# ATSAM4LC2C register map
Vendor: Atmel Corporation; Series: SAM4L; File version: B
CPU: CM4 r0p1, little endian, MPU, no FPU, 4 interrupt priority bits
Registers are 32-bit, write-only, reset 0x0 unless marked. A register's access mark holds for its fields unless they carry their own. Offsets are from the block's base; [hi:lo] are bit positions; {n}, {i} and the like mark numbered series; 'fields as' and 'values as' point back to an identical list.

## FREQM — Frequency Meter
Base 0x400E0C00; register names take the prefix FREQM_
0x00 CTRL — Control register
  [0] START — Start frequency measurement
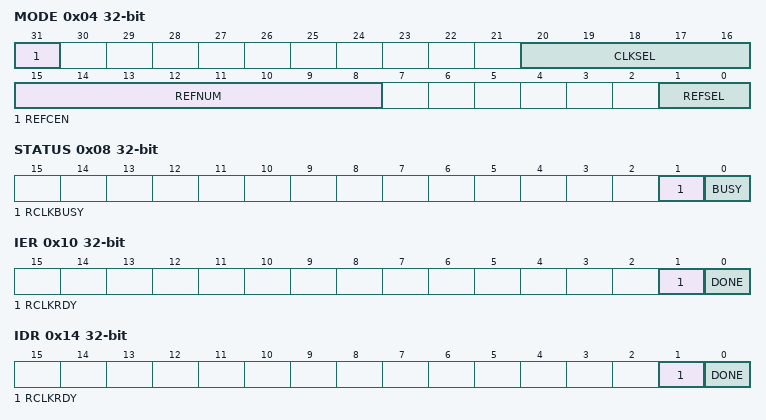
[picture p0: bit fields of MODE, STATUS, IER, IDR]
0x04 MODE rw
  [31] REFCEN — Reference Clock Enable
  [20:16] CLKSEL — Clock Source Selection
  [15:8] REFNUM — Number of Reference CLock Cycles
  [1:0] REFSEL — Reference Clock Selection
0x08 STATUS ro
  [1] RCLKBUSY — Reference Clock busy
  [0] BUSY — Frequency measurement on-going
0x0C VALUE ro
  [23:0] VALUE — Measured frequency
0x10 IER — Interrupt Enable Register
  [1] RCLKRDY — Reference Clock ready
  [0] DONE — Frequency measurment done
0x14 IDR — Interrupt Diable Register
  fields as IER
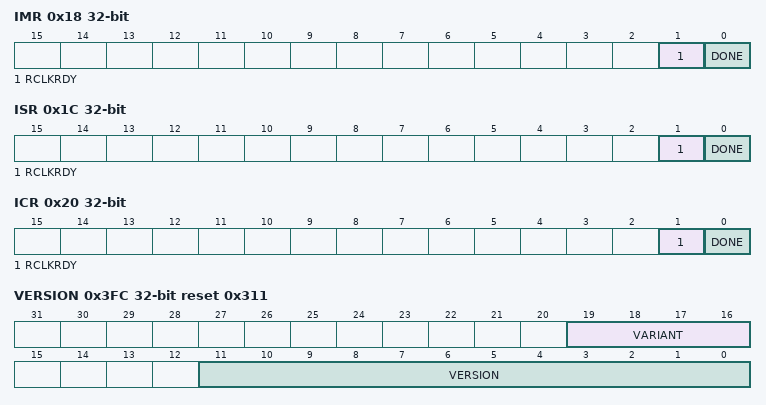
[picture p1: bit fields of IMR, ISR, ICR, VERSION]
0x18 IMR ro — Interrupt Mask Register
  fields as IER
0x1C ISR ro — Interrupt Status Register
  fields as IER
0x20 ICR — Interrupt Clear Register
  fields as IER
0x3FC VERSION ro reset 0x311
  [19:16] VARIANT — Variant number
  [11:0] VERSION — Version number

## GLOC — Glue Logic Controller
Base 0x40060000; register names take the prefix GLOC_
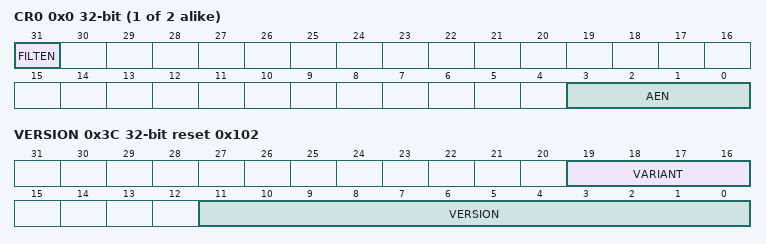
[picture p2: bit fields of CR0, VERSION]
{0x0+8i} CR{i} (i=0..1) rw — Control Register
  [31] FILTEN — Filter enable
  [3:0] AEN — Input mask
{0x4+8i} TRUTH{i} (i=0..1) rw
  [15:0] TRUTH
0x38 PARAMETER ro
  [7:0] LUTS
0x3C VERSION ro reset 0x102
  [19:16] VARIANT, [11:0] VERSION

## HCACHE — Cortex M I&D Cache Controller
Base 0x400A0400; register names take the prefix HCACHE_
0x08 CTRL — Control Register
  [0] CEN — Cache Enable
    0=NO (Disable Cache Controller); 1=YES (Enable Cache Controller)
0x0C SR rw — Status Register
  [0] CSTS ro — Cache Controller Status
    0=DIS (Cache Controller Disabled); 1=EN (Cache Controller Enabled)
0x20 MAINT0 — Maintenance Register 0
  [0] INVALL — Cache Controller Invalidate All
    0=NO (No effect); 1=YES (Invalidate all cache entries)
0x24 MAINT1 — Maintenance Register 1
  [7:4] INDEX — Invalidate Index
0x28 MCFG rw — Monitor Configuration Register
  [1:0] MODE — Cache Controller Monitor Counter Mode
    0=CYCLE (Cycle Counter); 1=IHIT (Instruction Hit Counter); 2=DHIT (Data Hit Counter)
0x2C MEN rw — Monitor Enable Register
  [0] MENABLE wo — Monitor Enable
    0=DIS (Disable Monitor Counter); 1=EN (Enable Monitor Counter)
0x30 MCTRL — Monitor Control Register
  [0] SWRST — Monitor Software Reset
    0=NO (No effect); 1=YES (Reset event counter register)
0x34 MSR ro — Monitor Status Register
  [31:0] EVENTCNT — Monitor Event Counter
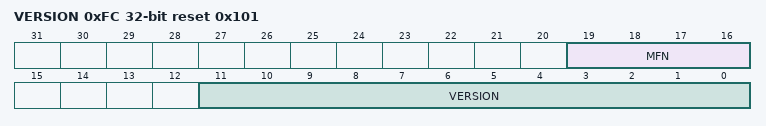
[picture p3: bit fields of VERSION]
0xFC VERSION ro reset 0x101
  [19:16] MFN, [11:0] VERSION

## HMATRIX — HSB Matrix
Base 0x400A1000; register names take the prefix HMATRIXB_
{0x0+4i} MCFG{i} (i=0..15) rw reset 0x2 — Master Configuration Register
  [2:0] ULBT — Undefined Length Burst Type
    0=INFINITE (Infinite Length); 1=SINGLE (Single Access); 2=FOUR_BEAT (Four Beat Burst); 3=EIGHT_BEAT (Eight Beat Burst); 4=SIXTEEN_BEAT (Sixteen Beat Burst)
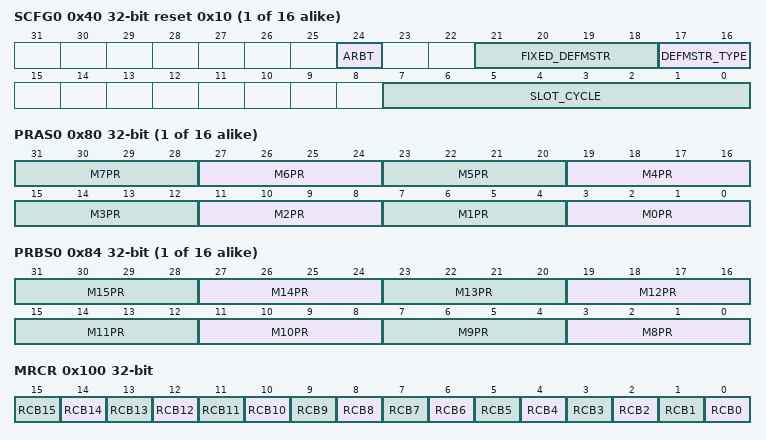
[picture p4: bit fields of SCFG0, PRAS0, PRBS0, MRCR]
{0x40+4i} SCFG{i} (i=0..15) rw reset 0x10 — Slave Configuration Register
  [24] ARBT — Arbitration Type
    0=ROUND_ROBIN (Round-Robin Arbitration); 1=FIXED_PRIORITY (Fixed Priority Arbitration)
  [21:18] FIXED_DEFMSTR — Fixed Index of Default Master
  [17:16] DEFMSTR_TYPE — Default Master Type
    0=NO_DEFAULT (No Default Master. At the end of current slave access, if no other master request is pending, the slave is deconnected from all masters. This resusts in having a one cycle latency for the first transfer of a burst.); 1=LAST_DEFAULT (Last Default Master At the end of current slave access, if no other master request is pending, the slave stay connected with the last master havingaccessed it.This resusts in not having the one cycle latency when the last master re-trying access on the slave.); 2=FIXED_DEFAULT (Fixed Default Master At the end of current slave access, if no other master request is pending, the slave connects with fixed master which numberis in FIXED_DEFMSTR register.This resusts in not having the one cycle latency when the fixed master re-trying access on the slave.)
  [7:0] SLOT_CYCLE — Maximum Number of Allowed Cycles for a Burst
{0x80+8i} PRAS{i} (i=0..15) rw — Priority Register A for Slave
  [4n+3:4n] M{n}PR (n=0..7) — Master {n} Priority
{0x84+8i} PRBS{i} (i=0..15) rw — Priority Register B for Slave
  [4n-29:4n-32] M{n}PR (n=8..15) — Master {n} Priority
0x100 MRCR rw — Master Remap Control Register
  [all] fields
    0=Disable remapped address decoding for master; 1=Enable remapped address decoding for master
  [n] RCB{n} (n=0..15) — Remap Command bit for Master {n}
{0x110+4i} SFR{i} (i=0..15) rw — Special Function Register
  [31:0] SFR

## Notices in the file
Atmel Microcontroller Software Support
Copyright (c) 2014, Atmel Corporation
All rights reserved.
Redistribution and use in source and binary forms, with or without
modification, are permitted provided that the following condition is met:
- Redistributions of source code must retain the above copyright notice,
this list of conditions and the disclaimer below.
Atmel's name may not be used to endorse or promote products derived from
this software without specific prior written permission.
DISCLAIMER: THIS SOFTWARE IS PROVIDED BY ATMEL "AS IS" AND ANY EXPRESS OR
IMPLIED WARRANTIES, INCLUDING, BUT NOT LIMITED TO, THE IMPLIED WARRANTIES OF
MERCHANTABILITY, FITNESS FOR A PARTICULAR PURPOSE AND NON-INFRINGEMENT ARE
DISCLAIMED. IN NO EVENT SHALL ATMEL BE LIABLE FOR ANY DIRECT, INDIRECT,
INCIDENTAL, SPECIAL, EXEMPLARY, OR CONSEQUENTIAL DAMAGES (INCLUDING, BUT NOT
LIMITED TO, PROCUREMENT OF SUBSTITUTE GOODS OR SERVICES; LOSS OF USE, DATA,
OR PROFITS; OR BUSINESS INTERRUPTION) HOWEVER CAUSED AND ON ANY THEORY OF
LIABILITY, WHETHER IN CONTRACT, STRICT LIABILITY, OR TORT (INCLUDING
NEGLIGENCE OR OTHERWISE) ARISING IN ANY WAY OUT OF THE USE OF THIS SOFTWARE,
EVEN IF ADVISED OF THE POSSIBILITY OF SUCH DAMAGE.
